# QN908XC register map
Vendor: nxp.com; File version: 1.0
CPU: CM4 r0p1, little endian, no MPU, no FPU, 0x3 interrupt priority bits, 0x0 interrupts
Registers are 32-bit, read-write, reset 0x0 unless marked. A register's access mark holds for its fields unless they carry their own. Offsets are from the block's base; [hi:lo] are bit positions; {n}, {i} and the like mark numbered series; <NAME> marks a mode.

## BLEDP
Base 0x4000E000
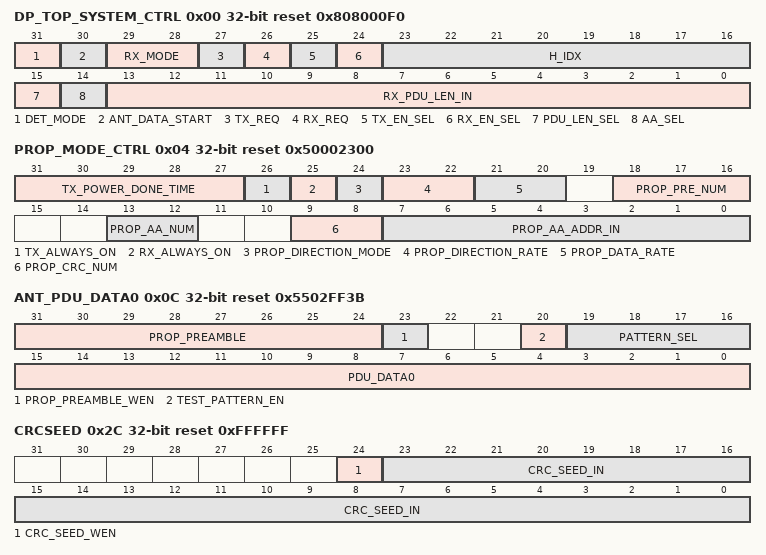
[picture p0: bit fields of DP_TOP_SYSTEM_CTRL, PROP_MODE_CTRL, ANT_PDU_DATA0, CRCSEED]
0x00 DP_TOP_SYSTEM_CTRL reset 0x808000F0 — datapath system control register
  [31] DET_MODE — detection mode 0low ppwer mode 1high performance mode.
  [30] ANT_DATA_START — ant mode data start signal need write 0 first then to 1.
  [29:28] RX_MODE
  [27] TX_REQ — tx request.
  [26] RX_REQ — rx request.
  [25] TX_EN_SEL — tx enable select signal
  [24] RX_EN_SEL — rx enable select signal
  [23:16] H_IDX — h index from 0.25 to 0.75 default is 0.5.
  [15] PDU_LEN_SEL — pdu length selection
  [14] AA_SEL — access address selection
  [13:0] RX_PDU_LEN_IN — pdu length user programmed header+payload unit is bit.
0x04 PROP_MODE_CTRL reset 0x50002300 — properity mode control register
  [31:27] TX_POWER_DONE_TIME — tx power down time in ant mode and prop mode unit is us.
  [26] TX_ALWAYS_ON
  [25] RX_ALWAYS_ON
  [24] PROP_DIRECTION_MODE — prop direction find mode just work at prop mode.
  [23:22] PROP_DIRECTION_RATE — prop direction find mode sample rate
  [21:20] PROP_DATA_RATE — prop mode data rate
  [18:16] PROP_PRE_NUM — prop mode preamble number
  [13:12] PROP_AA_NUM — prop mode network address number
  [9:8] PROP_CRC_NUM — prop mode crc number
  [7:0] PROP_AA_ADDR_IN — prop mode when access address is 5 byte the access address is {prop_aa_addr_in aa_addr_in} otherwise is aa_addr_in
0x08 ACCESS_ADDRESS reset 0x8E89BED6
  [31:0] AA_ADDR_IN — access address user programmed.
0x0C ANT_PDU_DATA0 reset 0x5502FF3B — pdu data 0 to 1 byte, and preamble register
  [31:24] PROP_PREAMBLE — prop mode preamble.
  [23] PROP_PREAMBLE_WEN — when high enable manual prop mode preamble.
  [20] TEST_PATTERN_EN — enable test pattern.
  [19:16] PATTERN_SEL — pattern selection
  [15:0] PDU_DATA0 — pdu data 0 to 1 byte
0x10 ANT_PDU_DATA1 reset 0x7BE2E64 — pdu data 2 to 5 byte
  [31:0] PDU_DATA1
0x14 ANT_PDU_DATA2 reset 0x129DA3CF — pdu data 6 to 9 byte
  [31:0] PDU_DATA2
0x18 ANT_PDU_DATA3 reset 0x9B15238D — pdu data 10 to 13 byte
  [31:0] PDU_DATA3
0x1C ANT_PDU_DATA4 reset 0xAB898880 — pdu data 14 to 17 byte
  [31:0] PDU_DATA4
0x20 ANT_PDU_DATA5 reset 0x42309CAB — pdu data 18 to 21 byte
  [31:0] PDU_DATA5
0x24 ANT_PDU_DATA6 reset 0xDE9B914 — pdu data 22 to 25 byte
  [31:0] PDU_DATA6
0x28 ANT_PDU_DATA7 reset 0x2B4FD925 — pdu data 26 to 29 byte
  [31:0] PDU_DATA7
0x2C CRCSEED reset 0xFFFFFF
  [24] CRC_SEED_WEN — when high enable manual program crc seed.
  [23:0] CRC_SEED_IN — user programmed crc seed.
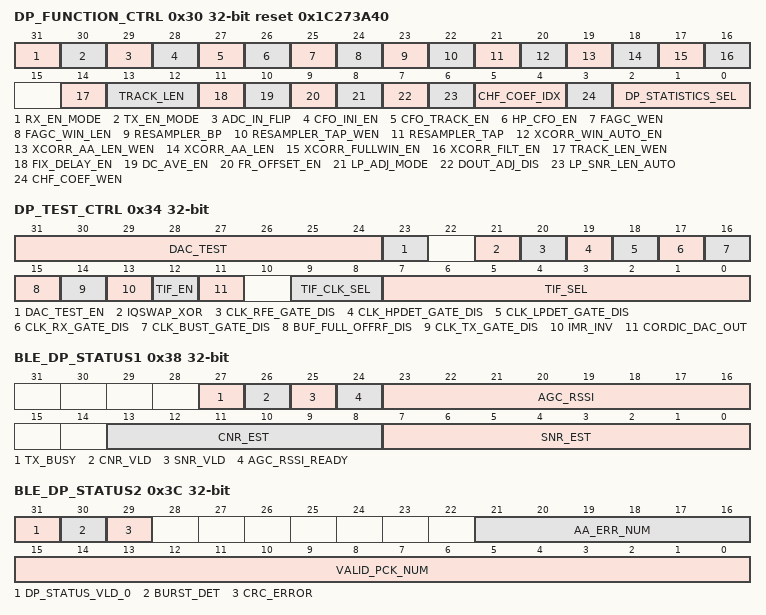
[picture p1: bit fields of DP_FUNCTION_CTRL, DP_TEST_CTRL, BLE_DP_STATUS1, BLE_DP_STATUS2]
0x30 DP_FUNCTION_CTRL reset 0x1C273A40 — datapath function control register
  [31] RX_EN_MODE — receiver mode
  [30] TX_EN_MODE — transmit mode
  [29] ADC_IN_FLIP — when 1 exchange i and q signals.
  [28] CFO_INI_EN — initial cfo enable.
  [27] CFO_TRACK_EN — tracking cfo enable.
  [26] HP_CFO_EN — when hp mode cfo estimation enable
  [25] FAGC_WEN — when high enable manual fine agc gain.
  [24] FAGC_WIN_LEN — select estimation length
  [23] RESAMPLER_BP — resampler enable or bypass
  [22] RESAMPLER_TAP_WEN — when high enable manual resampler tap number otherwise auto selection.
  [21] RESAMPLER_TAP — resampler tap number
  [20] XCORR_WIN_AUTO_EN — correlation window size auto selection enable.
  [19] XCORR_AA_LEN_WEN — enable manual correlation aa length.
  [18] XCORR_AA_LEN — select access address bit number
  [17] XCORR_FULLWIN_EN — when xcorr_win_auto_en low full sync enable.
  [16] XCORR_FILT_EN — when high enable xcorr filter.
  [14] TRACK_LEN_WEN — when high manual track length.
  [13:12] TRACK_LEN — track length
  [11] FIX_DELAY_EN
  [10] DC_AVE_EN — when high enable cfo estimation average.
  [9] FR_OFFSET_EN — pdu frequency offset track enable.
  [8] LP_ADJ_MODE — lp mode delay adjust mode
  [7] DOUT_ADJ_DIS — data delay adjust disable.
  [6] LP_SNR_LEN_AUTO — when enable auto adjust lp mode snr acc length otherwise the legnth fixed.
  [5:4] CHF_COEF_IDX
  [3] CHF_COEF_WEN — manual select channel filter coefficent.
  [2:0] DP_STATISTICS_SEL — datapath statistics selection.
0x34 DP_TEST_CTRL — datapath test iinterface register
  [31:24] DAC_TEST — dac input data value
  [23] DAC_TEST_EN — dac test enable dac input comes from register
  [21] IQSWAP_XOR
  [20] CLK_RFE_GATE_DIS — clock rfe gate disable
  [19] CLK_HPDET_GATE_DIS — clock hp mode detector gate disable
  [18] CLK_LPDET_GATE_DIS — clock lp mode detector gate disable
  [17] CLK_RX_GATE_DIS — clock rx gate disable
  [16] CLK_BUST_GATE_DIS — clock burst gate disable
  [15] BUF_FULL_OFFRF_DIS — (new standard)______when high rf always on in rx_en other wise when buffer full rf will be off.
  [14] CLK_TX_GATE_DIS — clock tx gate disable
  [13] IMR_INV — datapath mixer nco if selection
  [12] TIF_EN — test interface enable
  [11] CORDIC_DAC_OUT — when high cordic to dac
  [9:8] TIF_CLK_SEL — test interface clock selection
  [7:0] TIF_SEL — test interface selection.
0x38 BLE_DP_STATUS1 ro — datapath status register 1
  [27] TX_BUSY — tx busy signal.
  [26] CNR_VLD — cnr estimation valid.
  [25] SNR_VLD — snr estimation valid.
  [24] AGC_RSSI_READY — signal rssi valid.
  [23:16] AGC_RSSI — signal rssi db value.
  [13:8] CNR_EST — cnr estimation
  [7:0] SNR_EST — snr estimation
0x3C BLE_DP_STATUS2 ro — datapath status register 2
  [31] DP_STATUS_VLD_0 — data path status valid after access address valid.
  [30] BURST_DET — indicator of burst detection
  [29] CRC_ERROR — indicator of packet crc error.
  [21:16] AA_ERR_NUM — access address error number.
  [15:0] VALID_PCK_NUM — received valid packet number.
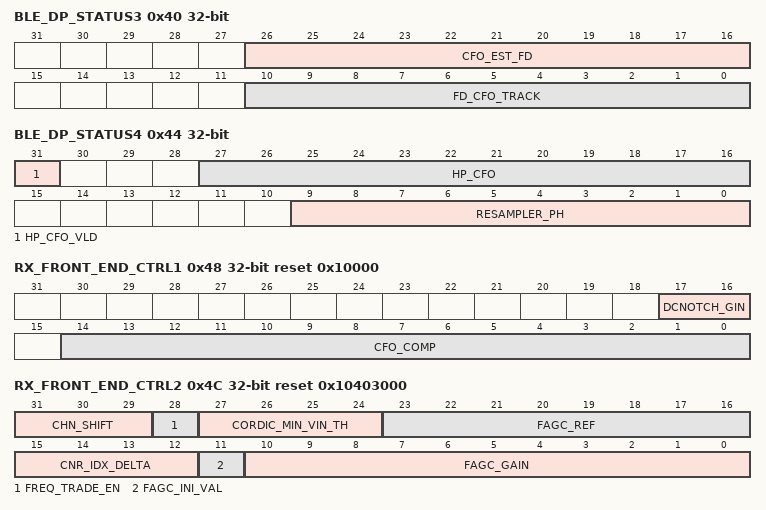
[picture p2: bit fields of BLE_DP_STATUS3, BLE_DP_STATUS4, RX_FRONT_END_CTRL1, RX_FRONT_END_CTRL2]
0x40 BLE_DP_STATUS3 ro — datapath status register 3
  [26:16] CFO_EST_FD — normalized lp cfo initial estimation.
  [10:0] FD_CFO_TRACK — normalized cfo tracking estimation.
0x44 BLE_DP_STATUS4 ro — datapath status register 4
  [31] HP_CFO_VLD — hp mode cfo estimation result valid
  [27:16] HP_CFO — normalized hp cfo estimation.
  [9:0] RESAMPLER_PH — resampler phase.
0x48 RX_FRONT_END_CTRL1 reset 0x10000 — rx front end control register 1
  [17:16] DCNOTCH_GIN — dc notch coefficient
  [14:0] CFO_COMP — ______cfo user programmed.
0x4C RX_FRONT_END_CTRL2 reset 0x10403000 — rx front end control register 2
  [31:29] CHN_SHIFT — channel filter shift
  [28] FREQ_TRADE_EN — enable frequency trade when cordic input signal small than cordic_min_vin_th
  [27:24] CORDIC_MIN_VIN_TH — cordic input signal min threshold
  [23:16] FAGC_REF — fine agc signal reference.
  [15:12] CNR_IDX_DELTA — cnr index delta.
  [11] FAGC_INI_VAL — fagc gain initial value
  [10:0] FAGC_GAIN — fine agc gain.
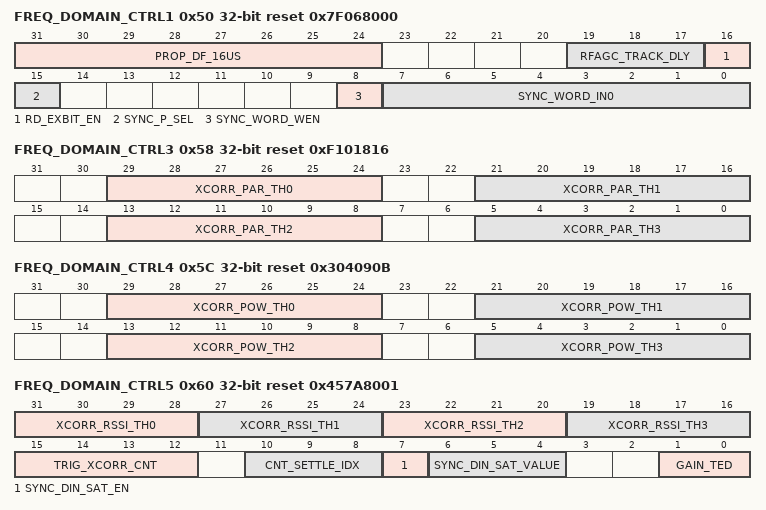
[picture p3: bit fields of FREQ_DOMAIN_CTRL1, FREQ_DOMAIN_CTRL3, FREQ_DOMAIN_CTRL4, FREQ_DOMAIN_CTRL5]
0x50 FREQ_DOMAIN_CTRL1 reset 0x7F068000 (reset mask 0xFF0E81FF) — frequency domain control register 1
  [31:24] PROP_DF_16US — prop mode direct found waiting 16 us.
  [19:17] RFAGC_TRACK_DLY — buffer settle threshold from 1us to 127us step is 1us
  [16] RD_EXBIT_EN — read extra 8 samples after sync
  [15] SYNC_P_SEL
  [8] SYNC_WORD_WEN — when high enable manul sync word
  [7:0] SYNC_WORD_IN0 — manul sync word [3932]
0x54 FREQ_DOMAIN_CTRL2 — frequency domain control register 2
  [31:0] SYNC_WORD_IN1 — manul sync word [310]
0x58 FREQ_DOMAIN_CTRL3 reset 0xF101816 — frequency domain control register 3
  [29-8n:24-8n] XCORR_PAR_TH{n} (n=0..3) — xcorr trigger par threshold{n}
0x5C FREQ_DOMAIN_CTRL4 reset 0x304090B — frequency domain control register 4
  [29-8n:24-8n] XCORR_POW_TH{n} (n=0..3) — xcorr power threshold{n}
0x60 FREQ_DOMAIN_CTRL5 reset 0x457A8001 — frequency domain control register 5
  [31-4n:28-4n] XCORR_RSSI_TH{n} (n=0..3) — xcorr triger rssi threshold0
  [15:12] TRIG_XCORR_CNT — correlation search window size.
  [10:8] CNT_SETTLE_IDX — buffer settle threshold from 32 to 256 step is 32
  [7] SYNC_DIN_SAT_EN — sync din amplitude limit enable
  [6:4] SYNC_DIN_SAT_VALUE — <u 1 2>sync din amplitude limit value 0 to 1.75 correspond to 2 to 3.75
  [1:0] GAIN_TED — ted gain
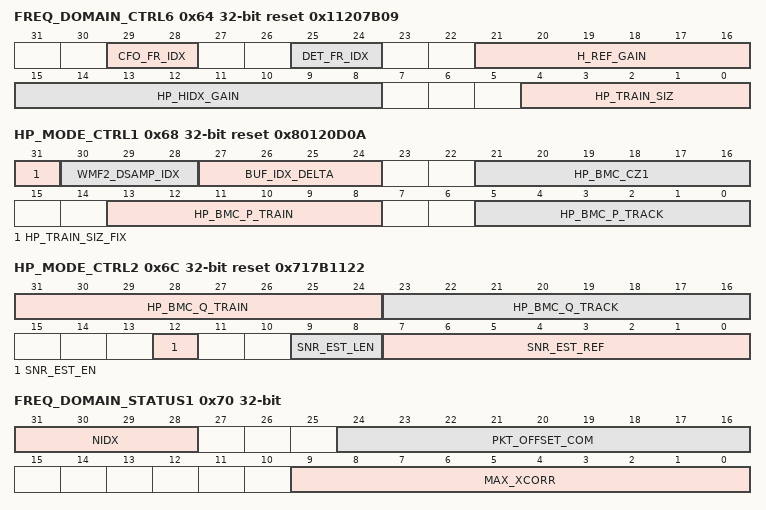
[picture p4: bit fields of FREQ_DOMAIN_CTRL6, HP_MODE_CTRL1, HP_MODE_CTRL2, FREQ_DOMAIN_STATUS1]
0x64 FREQ_DOMAIN_CTRL6 reset 0x11207B09 — frequency domain control register 5
  [29:28] CFO_FR_IDX — aa cfo tracking loop gain
  [25:24] DET_FR_IDX — pdu cfo tracking loop gain
  [21:16] H_REF_GAIN — h index reference gain when frequency offset track default is 1.0
  [15:8] HP_HIDX_GAIN — h index reference gain when hp mode default is 1.0
  [4:0] HP_TRAIN_SIZ — hp mode training size.
0x68 HP_MODE_CTRL1 reset 0x80120D0A — when high hp mode training size same as cfo tracking.
  [31] HP_TRAIN_SIZ_FIX — when high hp mode training size same as cfo tracking.
  [30:28] WMF2_DSAMP_IDX — wmf2 down sampling position -4 to 3
  [27:24] BUF_IDX_DELTA — buffer index delta
  [21:16] HP_BMC_CZ1 — cz1 parameter.
  [13:8] HP_BMC_P_TRAIN — p paramter in training period of frequency offset iir of bmc
  [5:0] HP_BMC_P_TRACK — p paramter in search period of frequency offset iir of bmc
0x6C HP_MODE_CTRL2 reset 0x717B1122 — q paramter in training period of phase offset iir of bmc
  [31:24] HP_BMC_Q_TRAIN — q paramter in training period of phase offset iir of bmc
  [23:16] HP_BMC_Q_TRACK — q paramter in search period of phase offset iir of bmc
  [12] SNR_EST_EN — snr estimation in time domain enable
  [9:8] SNR_EST_LEN — symbol number used in snr estimation when pdu length is less than 4 8 32 will be used otherwise the value configured from register will be used
  [7:0] SNR_EST_REF — signal amplitude used in snr estimation whose unit is db
0x70 FREQ_DOMAIN_STATUS1 ro — frequency domain status register 1
  [31:28] NIDX — noise db buffer index
  [24:16] PKT_OFFSET_COM — time from access addres last bit to trigger finish.
  [9:0] MAX_XCORR — xcorr_org value at the max par position
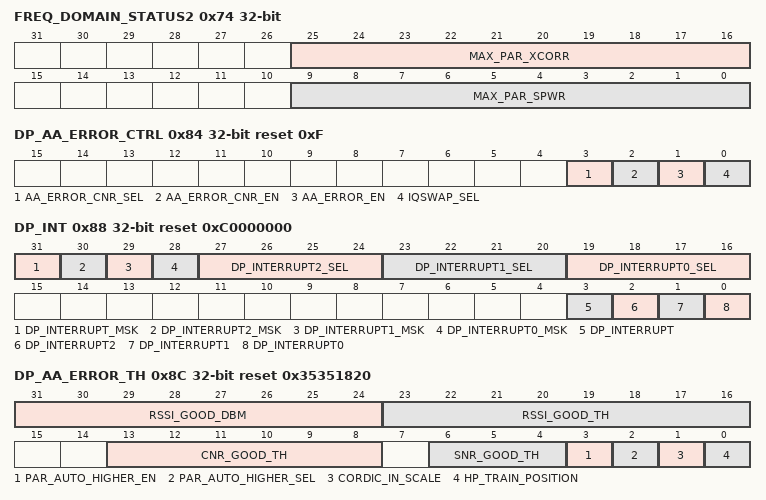
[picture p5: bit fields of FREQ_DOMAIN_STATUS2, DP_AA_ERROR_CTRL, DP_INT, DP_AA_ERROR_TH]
0x74 FREQ_DOMAIN_STATUS2 ro — frequency domain status register 2
  [25:16] MAX_PAR_XCORR — xcorr*xcorr value at the max par position
  [9:0] MAX_PAR_SPWR — spwr value at the max par position
0x84 DP_AA_ERROR_CTRL reset 0xF — AA error control register
  [3] AA_ERROR_CNR_SEL — when high the cnr threshold is 24. when low the cnr threshold is 32.
  [2] AA_ERROR_CNR_EN — when high the aa error reset condition is cnr > threshold and aa error. when low it don care cnr.
  [1] AA_ERROR_EN — when high it will reset datapath when aa error.
  [0] IQSWAP_SEL — when high adc data iq swap with analog iqswap. datapath mixer nco if selection changed with analog iqswap.
0x88 DP_INT reset 0xC0000000 — data path interrupt register
  [31] DP_INTERRUPT_MSK — datapath interrupt msk
  [30] DP_INTERRUPT2_MSK — datapath interrupt2 msk
  [29] DP_INTERRUPT1_MSK — datapath interrupt1 msk
  [28] DP_INTERRUPT0_MSK — datapath interrupt0 msk
  [27:24] DP_INTERRUPT2_SEL — datapath interrupt2 selection
  [23:20] DP_INTERRUPT1_SEL — datapath interrupt1 selection
  [19:16] DP_INTERRUPT0_SEL — datapath interrupt0 selection
  [3] DP_INTERRUPT ro — datapath interrupt
  [2] DP_INTERRUPT2 ro — datapath interrupt2
  [1] DP_INTERRUPT1 ro — datapath interrupt1
  [0] DP_INTERRUPT0 ro — datapath interrupt0
0x8C DP_AA_ERROR_TH reset 0x35351820 — AA error threshold register
  [31:24] RSSI_GOOD_DBM — when rssi dbm large than the -rssi_good_dbm the signal is good enough to higher the par threshold if the function enable.
  [23:16] RSSI_GOOD_TH — threshold for rssi to reset datapath cooperate with cnr snr and aa error.
  [13:8] CNR_GOOD_TH — threshold for cnr to reset datapath cooperate with cnr snr and aa error.
  [6:4] SNR_GOOD_TH — threshold for snr(fd mode calculated use aa) to reset datapath cooperate with cnr snr and aa error.
  [3] PAR_AUTO_HIGHER_EN — when high when signal is good ( rssi large than rssi_good_dbm) it will auto higher the par threshold.
  [2] PAR_AUTO_HIGHER_SEL — when high par auto higher 1/4 when low par auto higher 1/8 it will work together with par_auto_higher_en and rssi_good_dbm.
  [1] CORDIC_IN_SCALE — when high cordic input will be auto scaled(shift) according to the magnitude of real/imag data.
  [0] HP_TRAIN_POSITION — when high use the bits just ahead of pdu for rsve training. when low the training bit starts at the track bits.
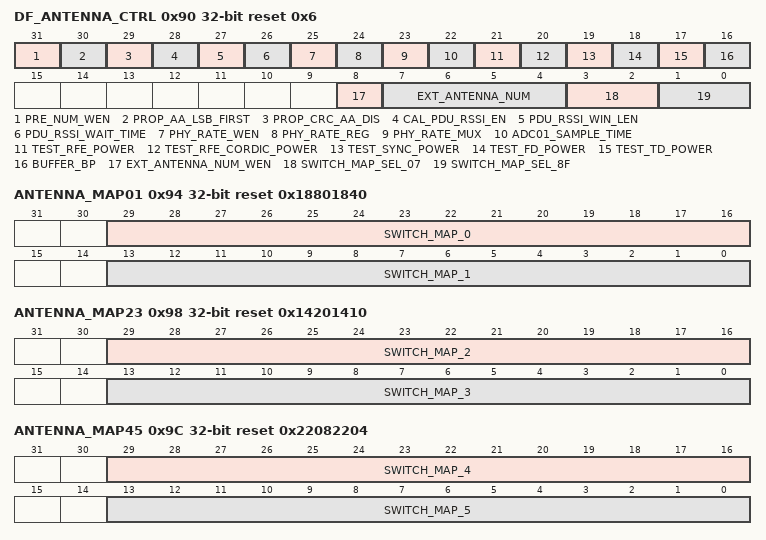
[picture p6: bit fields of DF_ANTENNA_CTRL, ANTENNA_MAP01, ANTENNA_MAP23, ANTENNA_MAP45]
0x90 DF_ANTENNA_CTRL reset 0x6 — antenna register
  [31] PRE_NUM_WEN — preamble number write enable
  [30] PROP_AA_LSB_FIRST — prop mode access address lsb first for cbt test.
  [29] PROP_CRC_AA_DIS — prop mode crc check disable check access address.
  [28] CAL_PDU_RSSI_EN — calculate rssi use pdu data enbale.
  [27] PDU_RSSI_WIN_LEN — select estimation length for pdu rssi calculate
  [26] PDU_RSSI_WAIT_TIME — 0:wait 0us 1: wait 4us
  [25] PHY_RATE_WEN — 0: phy rate comes from ble ip 1:phy rate comes from regsiter phy_rate_reg
  [24] PHY_RATE_REG — user programmed phy data rate
  [23] PHY_RATE_MUX ro — ble data rate used in datapath, 0: 1mbps 1: 2mbps
  [22] ADC01_SAMPLE_TIME — when high, will exchange the adc0/adc1 sample time, to avoid the error sample time for adc0/adc1
  [21] TEST_RFE_POWER — when high, test rfe power, other module don't work
  [20] TEST_RFE_CORDIC_POWER — when high, test rfe and cordic power, other module don't work
  [19] TEST_SYNC_POWER — when high, test rfe. Cordic and sync power. Other module don't work
  [18] TEST_FD_POWER — when high, test rfe, cordic and fd detector power, other module don't work
  [17] TEST_TD_POWER — when high, test rfe,td detector power, other module don't work, the cordic work or not decided by resampler_bp
  [16] BUFFER_BP — when high, bypass buffer, and not write/read buffer for datapath power test
  [8] EXT_ANTENNA_NUM_WEN — user programmed switch antenna enable
  [7:4] EXT_ANTENNA_NUM — user programmed switch antenna number
  [3:2] SWITCH_MAP_SEL_07 — switch antenna map selection 0 to 7
  [1:0] SWITCH_MAP_SEL_8F — switch antenna map selection 8 to f
0x94 ANTENNA_MAP01 reset 0x18801840 — antenna switch map register 0
  [29:16] SWITCH_MAP_0 — switch antenna map 0
  [13:0] SWITCH_MAP_1 — switch antenna map 1
0x98 ANTENNA_MAP23 reset 0x14201410 — antenna switch map register 1
  [29:16] SWITCH_MAP_2 — switch antenna map 2
  [13:0] SWITCH_MAP_3 — switch antenna map 3
0x9C ANTENNA_MAP45 reset 0x22082204 — antenna switch map register 2
  [29:16] SWITCH_MAP_4 — switch antenna map 4
  [13:0] SWITCH_MAP_5 — switch antenna map 5
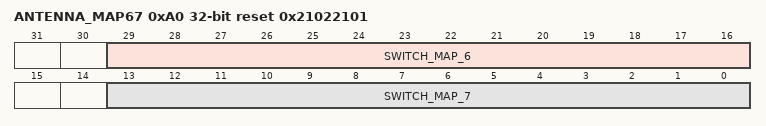
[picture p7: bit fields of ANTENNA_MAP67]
0xA0 ANTENNA_MAP67 reset 0x21022101 — antenna switch map register 3
  [29:16] SWITCH_MAP_6 — switch antenna map 6
  [13:0] SWITCH_MAP_7 — switch antenna map 7
